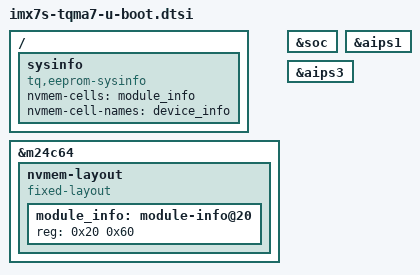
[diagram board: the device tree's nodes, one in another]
// SPDX-License-Identifier: GPL-2.0-or-later OR MIT
/*
 * Device Tree Source for TQ-Systems TQMa7S module.
 *
 * Copyright (C) 2024-2026 TQ-Systems GmbH <u-boot@ew.tq-group.com>,
 * D-82229 Seefeld, Germany
 * Author: Steffen Doster
 */

#include "imx7s-u-boot.dtsi"

/ {
	sysinfo: sysinfo {
		compatible = "tq,eeprom-sysinfo";
		nvmem-cells = <&module_info>;
		nvmem-cell-names = "device_info";
	};
};

&m24c64 {
	nvmem-layout {
		compatible = "fixed-layout";
		#address-cells = <1>;
		#size-cells = <1>;

		module_info: module-info@20 {
			reg = <0x20 0x60>;
		};
	};
};

&soc {
	bootph-pre-ram;
};

&aips1 {
	bootph-pre-ram;
};

&aips3 {
	bootph-pre-ram;
};
